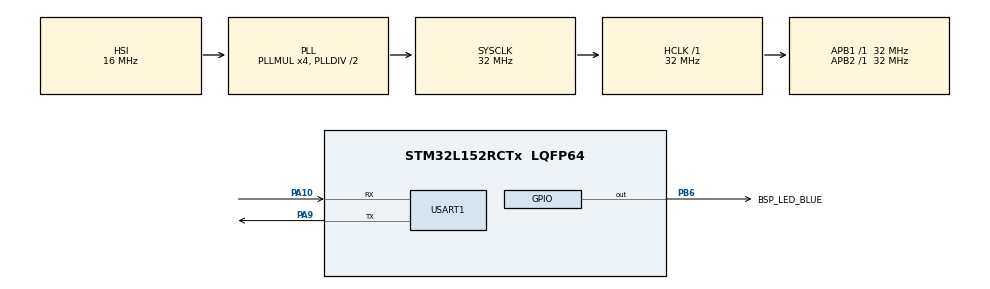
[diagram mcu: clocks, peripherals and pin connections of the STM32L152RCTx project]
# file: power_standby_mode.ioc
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Mcu.Family=STM32L1
Mcu.Name=STM32L152RCTx
Mcu.Package=LQFP64
NVIC.PriorityGroup=NVIC_PRIORITYGROUP_0
NVIC.RTC_WKUP_IRQn=true\:0\:0\:false\:false\:true\:true\:true\:true
PA0-WKUP1.Mode=SYS_WakeUp0
PA0-WKUP1.Signal=SYS_WKUP1
PA10.Mode=Asynchronous
PA10.Signal=USART1_RX
PA13.Mode=Serial_Wire
PA13.Signal=SYS_JTMS-SWDIO
PA14.Mode=Serial_Wire
PA14.Signal=SYS_JTCK-SWCLK
PA9.Mode=Asynchronous
PA9.Signal=USART1_TX
PB6.GPIO_Label=BSP_LED_BLUE
PB6.Signal=GPIO_Output
PH0-OSC_IN.Mode=HSE-External-Oscillator
PH0-OSC_IN.Signal=RCC_OSC_IN
PH1-OSC_OUT.Mode=HSE-External-Oscillator
PH1-OSC_OUT.Signal=RCC_OSC_OUT
ProjectManager.HeapSize=0x200
ProjectManager.StackSize=0x400
ProjectManager.TargetToolchain=STM32CubeIDE
RCC.48MHZClocksFreq_Value=32000000
RCC.AHBFreq_Value=32000000
RCC.APB1Freq_Value=32000000
RCC.APB1TimFreq_Value=32000000
RCC.APB2Freq_Value=32000000
RCC.APB2TimFreq_Value=32000000
RCC.HCLKFreq_Value=32000000
RCC.HSE_VALUE=8000000
RCC.HSI_VALUE=16000000
RCC.MSI_VALUE=2097000
RCC.PLLMUL=RCC_PLL_MUL4
RCC.RTCClockSelection=RCC_RTCCLKSOURCE_LSI
RCC.RTCClockSelectionVirtual=RCC_RTCCLKSOURCE_LSE
RCC.SYSCLKFreq_VALUE=32000000
RCC.SYSCLKSource=RCC_SYSCLKSOURCE_PLLCLK
RCC.USBOutput=48000000
RCC.VCOOutputFreq_Value=64000000
USART1.VirtualMode=VM_ASYNC
VP_RTC_VS_RTC_Activate.Mode=RTC_Enabled
VP_RTC_VS_RTC_WakeUp_intern.Mode=WakeUp
board=STM32L152C-DISCO

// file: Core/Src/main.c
/* USER CODE BEGIN Header */
/**
 ******************************************************************************
 * @file           : main.c
 * @brief          : Main program body
 ******************************************************************************
 * @attention
 *
 * Copyright (c) 2023 STMicroelectronics.
 * All rights reserved.
 *
 * This software is licensed under terms that can be found in the LICENSE file
 * in the root directory of this software component.
 * If no LICENSE file comes with this software, it is provided AS-IS.
 *
 ******************************************************************************
 */
/* USER CODE END Header */
#include "main.h"

/* USER CODE BEGIN Includes */
#include "stdio.h"
#include "string.h"
/* USER CODE END Includes */

RTC_HandleTypeDef hrtc;

UART_HandleTypeDef huart1;

void SystemClock_Config(void);
static void MX_GPIO_Init(void);
static void MX_USART1_UART_Init(void);
static void MX_RTC_Init(void);

int main(void) {

	/* MCU Configuration--------------------------------------------------------*/

	/* Reset of all peripherals, Initializes the Flash interface and the Systick. */
	HAL_Init();

	/* Configure the system clock */
	SystemClock_Config();

	/* Initialize all configured peripherals */
	MX_GPIO_Init();
	MX_USART1_UART_Init();
	MX_RTC_Init();
	/* USER CODE BEGIN 2 */

	// stand my mode is used for lovest power cunsuption
	//deep sleap mode power is desable so powered off
	// and  The PLLs, the HSI oscillator and the HSE oscillator are also switched off.
//** check if SB flag is set....**
	if (__HAL_PWR_GET_FLAG(PWR_FLAG_SB) != RESET) {
		__HAL_PWR_CLEAR_FLAG(PWR_FLAG_SB); // clear the flag disable the wakeup flags
//the sbf status flag in the pwr power control status registor indicate that the mcu was stand by mode.

		/** display  the string **/
		char *str = "Wakeup from the STANDBY MODE\n\n";
		HAL_UART_Transmit(&huart1, (uint8_t*) str, strlen(str), HAL_MAX_DELAY);
//start the
		/** Blink the LED for few time in small delay **/
		for (int i = 0; i < 20; i++) {
			HAL_GPIO_TogglePin(BSP_LED_BLUE_GPIO_Port, BSP_LED_BLUE_Pin);
			HAL_Delay(200);
		}
		//***...  Disable the WWAKEUP PIN *****
		HAL_PWR_DisableWakeUpPin(PWR_WAKEUP_PIN1);  // disable PA0

		/** Deactivate the RTC wakeup  **/
		HAL_RTCEx_DeactivateWakeUpTimer(&hrtc);

	}
	/** Now enter the standby mode **/
	/* Clear the WU FLAG */
	__HAL_PWR_CLEAR_FLAG(PWR_FLAG_WU);

	/* clear the RTC Wake UP (WU) flag */
	__HAL_RTC_WAKEUPTIMER_CLEAR_FLAG(&hrtc, RTC_FLAG_WUTF);

	/** display  the string **/
	char *str = "ABOUT TO ENTER THE STANDBY MODE\n\n";
	HAL_UART_Transmit(&huart1, (uint8_t*) str, strlen(str), HAL_MAX_DELAY);

	/** Blink the LED for few time in small delay **/
	for (int i = 0; i < 5; i++) {
		HAL_GPIO_TogglePin(BSP_LED_BLUE_GPIO_Port, BSP_LED_BLUE_Pin);
		HAL_Delay(750);
	}

	/* Enable the WAKEUP PIN */
	HAL_PWR_EnableWakeUpPin(PWR_WAKEUP_PIN1);

	/* enable the RTC Wakeup */
	/*  RTC Wake-up Interrupt Generation:
	 Wake-up Time Base = (RTC_WAKEUPCLOCK_RTCCLK_DIV /(LSI))
	 ==> WakeUpCounter = Wake-up Time / Wake-up Time Base

	 To configure the wake up timer to 5s the WakeUpCounter is set to 0x2710:
	 RTC_WAKEUPCLOCK_RTCCLK_DIV = RTCCLK_Div16 = 16
	 Wake-up Time Base = 16 /(32KHz) = 0.0005 seconds
	 ==> WakeUpCounter = ~5s/0.0005s = 20000 = 0x2710
	 */
// enable the wakeup pin, or the RTC periodic wakeup
	if (HAL_RTCEx_SetWakeUpTimer_IT(&hrtc, 0x5A55, RTC_WAKEUPCLOCK_RTCCLK_DIV16)
			!= HAL_OK) {
		Error_Handler();
	}

// The standby wakeup is same as a system RESET. The entire code runs from the beginning
//just as if it was a RESET. The only difference between a reset and a STANDBY wakeup is
	//that, when the MCU wakesup, The SBF status flag in the PWR power control/status
	//register (PWR_CSR) is set. The wakeup can be triggered by WKUP pin rising edge, RTC
	// RTC wakeup, tamper event, time stamp event, external reset in NRST pin, IWDG reset.

	/* one last string to be sure */
	char *str2 = "STANDBY MODE is ON\n\n";
	HAL_UART_Transmit(&huart1, (uint8_t*) str2, strlen(str2),
	HAL_MAX_DELAY);

	/* Finally enter the standby mode */
	HAL_PWR_EnterSTANDBYMode();

	/* USER CODE END 2 */

	/* Infinite loop */
	while (1) {

	}
}

void SystemClock_Config(void) {
	RCC_OscInitTypeDef RCC_OscInitStruct = { 0 };
	RCC_ClkInitTypeDef RCC_ClkInitStruct = { 0 };
	RCC_PeriphCLKInitTypeDef PeriphClkInit = { 0 };

	/** Configure the main internal regulator output voltage
	 */
	__HAL_PWR_VOLTAGESCALING_CONFIG(PWR_REGULATOR_VOLTAGE_SCALE1);

	/** Initializes the RCC Oscillators according to the specified parameters
	 * in the RCC_OscInitTypeDef structure.
	 */
	RCC_OscInitStruct.OscillatorType = RCC_OSCILLATORTYPE_HSI
			| RCC_OSCILLATORTYPE_LSI;
	RCC_OscInitStruct.HSIState = RCC_HSI_ON;
	RCC_OscInitStruct.HSICalibrationValue = RCC_HSICALIBRATION_DEFAULT;
	RCC_OscInitStruct.LSIState = RCC_LSI_ON;
	RCC_OscInitStruct.PLL.PLLState = RCC_PLL_ON;
	RCC_OscInitStruct.PLL.PLLSource = RCC_PLLSOURCE_HSI;
	RCC_OscInitStruct.PLL.PLLMUL = RCC_PLL_MUL4;
	RCC_OscInitStruct.PLL.PLLDIV = RCC_PLL_DIV2;
	if (HAL_RCC_OscConfig(&RCC_OscInitStruct) != HAL_OK) {
		Error_Handler();
	}

	/** Initializes the CPU, AHB and APB buses clocks
	 */
	RCC_ClkInitStruct.ClockType = RCC_CLOCKTYPE_HCLK | RCC_CLOCKTYPE_SYSCLK
			| RCC_CLOCKTYPE_PCLK1 | RCC_CLOCKTYPE_PCLK2;
	RCC_ClkInitStruct.SYSCLKSource = RCC_SYSCLKSOURCE_PLLCLK;
	RCC_ClkInitStruct.AHBCLKDivider = RCC_SYSCLK_DIV1;
	RCC_ClkInitStruct.APB1CLKDivider = RCC_HCLK_DIV1;
	RCC_ClkInitStruct.APB2CLKDivider = RCC_HCLK_DIV1;

	if (HAL_RCC_ClockConfig(&RCC_ClkInitStruct, FLASH_LATENCY_1) != HAL_OK) {
		Error_Handler();
	}
	PeriphClkInit.PeriphClockSelection = RCC_PERIPHCLK_RTC;
	PeriphClkInit.RTCClockSelection = RCC_RTCCLKSOURCE_LSI;
	if (HAL_RCCEx_PeriphCLKConfig(&PeriphClkInit) != HAL_OK) {
		Error_Handler();
	}
}

static void MX_RTC_Init(void) {

	RTC_TimeTypeDef sTime = { 0 };
	RTC_DateTypeDef sDate = { 0 };

	/** Initialize RTC Only
	 */
	hrtc.Instance = RTC;
	hrtc.Init.HourFormat = RTC_HOURFORMAT_24;
	hrtc.Init.AsynchPrediv = 127;
	hrtc.Init.SynchPrediv = 255;
	hrtc.Init.OutPut = RTC_OUTPUT_DISABLE;
	hrtc.Init.OutPutPolarity = RTC_OUTPUT_POLARITY_HIGH;
	hrtc.Init.OutPutType = RTC_OUTPUT_TYPE_OPENDRAIN;
	if (HAL_RTC_Init(&hrtc) != HAL_OK) {
		Error_Handler();
	}

	/** Initialize RTC and set the Time and Date
	 */
	sTime.Hours = 0x0;
	sTime.Minutes = 0x0;
	sTime.Seconds = 0x0;
	sTime.DayLightSaving = RTC_DAYLIGHTSAVING_NONE;
	sTime.StoreOperation = RTC_STOREOPERATION_RESET;
	if (HAL_RTC_SetTime(&hrtc, &sTime, RTC_FORMAT_BCD) != HAL_OK) {
		Error_Handler();
	}
	sDate.WeekDay = RTC_WEEKDAY_MONDAY;
	sDate.Month = RTC_MONTH_JANUARY;
	sDate.Date = 0x1;
	sDate.Year = 0x0;

	if (HAL_RTC_SetDate(&hrtc, &sDate, RTC_FORMAT_BCD) != HAL_OK) {
		Error_Handler();
	}

	/** Enable the WakeUp
	 */
	if (HAL_RTCEx_SetWakeUpTimer_IT(&hrtc, 0, RTC_WAKEUPCLOCK_RTCCLK_DIV16)
			!= HAL_OK) {
		Error_Handler();
	}

}

static void MX_USART1_UART_Init(void) {

	huart1.Instance = USART1;
	huart1.Init.BaudRate = 115200;
	huart1.Init.WordLength = UART_WORDLENGTH_8B;
	huart1.Init.StopBits = UART_STOPBITS_1;
	huart1.Init.Parity = UART_PARITY_NONE;
	huart1.Init.Mode = UART_MODE_TX_RX;
	huart1.Init.HwFlowCtl = UART_HWCONTROL_NONE;
	huart1.Init.OverSampling = UART_OVERSAMPLING_16;
	if (HAL_UART_Init(&huart1) != HAL_OK) {
		Error_Handler();
	}

}

static void MX_GPIO_Init(void) {
	GPIO_InitTypeDef GPIO_InitStruct = { 0 };

	/* GPIO Ports Clock Enable */
	__HAL_RCC_GPIOH_CLK_ENABLE();
	__HAL_RCC_GPIOA_CLK_ENABLE();
	__HAL_RCC_GPIOB_CLK_ENABLE();

	/*Configure GPIO pin Output Level */
	HAL_GPIO_WritePin(BSP_LED_BLUE_GPIO_Port, BSP_LED_BLUE_Pin, GPIO_PIN_RESET);

	/*Configure GPIO pin : BSP_LED_BLUE_Pin */
	GPIO_InitStruct.Pin = BSP_LED_BLUE_Pin;
	GPIO_InitStruct.Mode = GPIO_MODE_OUTPUT_PP;
	GPIO_InitStruct.Pull = GPIO_NOPULL;
	GPIO_InitStruct.Speed = GPIO_SPEED_FREQ_LOW;
	HAL_GPIO_Init(BSP_LED_BLUE_GPIO_Port, &GPIO_InitStruct);

}

void Error_Handler(void) {
	__disable_irq();
	while (1) {
	}
}
